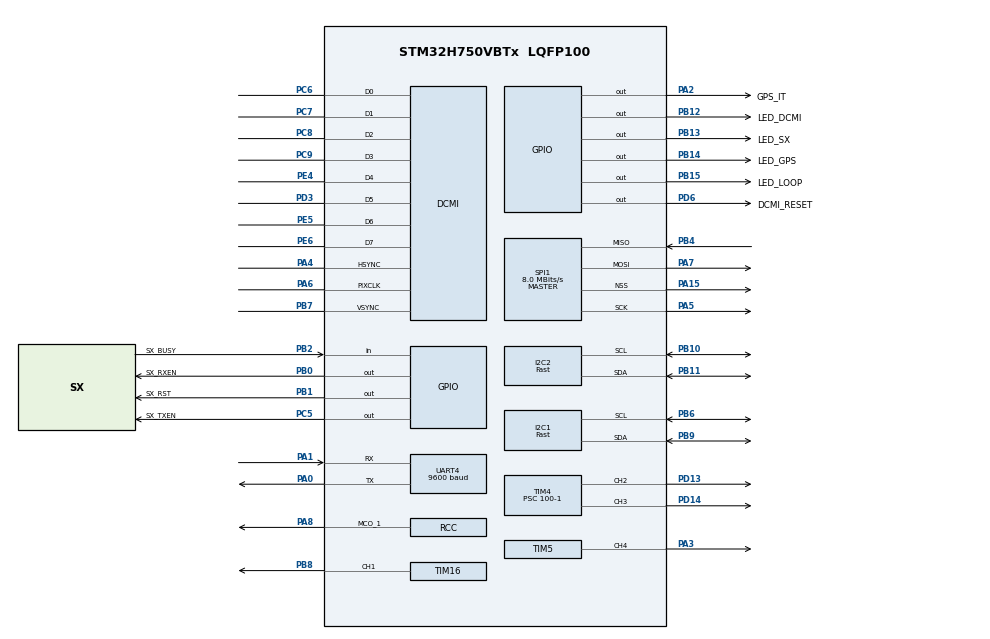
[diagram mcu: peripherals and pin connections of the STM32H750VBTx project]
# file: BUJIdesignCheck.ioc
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VP_TIM5_VS_ClockSourceINT.Mode=Internal
Dma.UART4_RX.1.Mode=DMA_CIRCULAR
Dma.UART4_RX.1.MemDataAlignment=DMA_MDATAALIGN_BYTE
I2C1.I2C_Speed_Mode=I2C_Fast
SPI1.VirtualType=VM_MASTER
PB10.Mode=I2C
RCC.PLL2_VCI_Range-AdvancedSettings=RCC_PLL2VCIRANGE_0
PB14.GPIO_Label=LED_GPS
Dma.DCMI.0.MemBurst=DMA_MBURST_SINGLE
PA15\ (JTDI).Signal=SPI1_NSS
PB13.Signal=GPIO_Output
PD6.GPIO_Label=DCMI_RESET
RCC.SYSCLKSource=RCC_SYSCLKSOURCE_PLLCLK
Dma.UART4_RX.1.SyncPolarity=HAL_DMAMUX_SYNC_NO_EVENT
Dma.DCMI.0.MemDataAlignment=DMA_MDATAALIGN_WORD
RCC.SPI123CLockSelection=RCC_SPI123CLKSOURCE_CLKP
PA15\ (JTDI).Mode=NSS_Signal_Hard_Output
PA14\ (JTCK/SWCLK).Signal=DEBUG_JTCK-SWCLK
PA4.Mode=Slave_8_bits_External_Synchro
Dma.DCMI.0.PeriphDataAlignment=DMA_PDATAALIGN_WORD
SPI1.Direction=SPI_DIRECTION_2LINES
I2C2.I2C_Speed_Mode=I2C_Fast
PB6.Signal=I2C1_SCL
PC7.Signal=DCMI_D1
PB12.PinState=GPIO_PIN_SET
PB6.Mode=I2C
SPI1.CalculateBaudRate=8.0 MBits/s
UART4.Parity=PARITY_NONE
PE5.Signal=DCMI_D6
Dma.UART4_RX.1.FIFOMode=DMA_FIFOMODE_DISABLE
TIM4.Channel-PWM\ Generation3\ CH3=TIM_CHANNEL_3
PB2.Signal=GPIO_Input
RCC.DIVM1=8
DCMI.PCKPolarity=DCMI_PCKPOLARITY_RISING
PB12.GPIO_Label=LED_DCMI
PB1.GPIO_Label=SX_RST
SPI1.DataSize=SPI_DATASIZE_8BIT
PA0.Mode=Asynchronous
PC9.Mode=Slave_8_bits_External_Synchro
SH.S_TIM4_CH2.0=TIM4_CH2,PWM Generation2 CH2
PA8.Signal=RCC_MCO_1
Dma.DCMI.0.Polarity=HAL_DMAMUX_REQ_GEN_RISING
PA14\ (JTCK/SWCLK).Mode=Serial_Wire
SPI1.VirtualNSS=VM_NSSHARD
RCC.PLL2_VCO_SEL-AdvancedSettings=RCC_PLL2VCOMEDIUM
TIM4.Period=5000-1
PD3.Mode=Slave_8_bits_External_Synchro
PA0.Signal=UART4_TX
Mcu.Package=LQFP100
PB9.Signal=I2C1_SDA
PB1.Signal=GPIO_Output
Dma.UART4_RX.1.PeriphDataAlignment=DMA_PDATAALIGN_BYTE
RCC.APB4Freq_Value=100000000
TIM16.Prescaler=100-1
I2C1.CustomTiming=Disabled
PH0-OSC_IN\ (PH0).Mode=HSE-External-Oscillator
NVIC.UART4_IRQn=true\:0\:0\:false\:false\:true\:true\:true
PA5.Mode=Full_Duplex_Master
TIM3.AutoReloadPreload=TIM_AUTORELOAD_PRELOAD_ENABLE
PD3.Signal=DCMI_D5
PC6.Signal=DCMI_D0
Dma.UART4_RX.1.SyncRequestNumber=1
SH.S_TIM16_CH1.0=TIM16_CH1,PWM Generation1 CH1
VP_TIM16_VS_ClockSourceINT.Mode=Enable_Timer
RCC.Tim2Mul=2
PB11.Mode=I2C
PC6.Mode=Slave_8_bits_External_Synchro
I2C1.Timing=0x009034B6
RCC.DIVN1=200
UART4.FIFOMode=FIFOMODE_DISABLE
PB10.Signal=I2C2_SCL
DCMI.JPEGMode=DCMI_JPEG_ENABLE
PB14.Signal=GPIO_Output
PA5.Signal=SPI1_SCK
Dma.DCMI.0.EventEnable=DISABLE
NVIC.TIM3_IRQn=true\:0\:0\:false\:false\:true\:true\:true
PA1.Mode=Asynchronous
PB13.PinState=GPIO_PIN_SET
PE6.Mode=Slave_8_bits_External_Synchro
PB15.GPIO_Label=LED_LOOP
SPI1.Mode=SPI_MODE_MASTER
PB4\ (NJTRST).Mode=Full_Duplex_Master
PC8.Mode=Slave_8_bits_External_Synchro
PA4.Signal=DCMI_HSYNC
ProjectManager.HeapSize=0x200
Dma.UART4_RX.1.PeriphInc=DMA_PINC_DISABLE
Dma.DCMI.0.SignalID=NONE
VP_TIM4_VS_ClockSourceINT.Mode=Internal
NVIC.PriorityGroup=NVIC_PRIORITYGROUP_4
Dma.UART4_RX.1.Priority=DMA_PRIORITY_LOW
PA8.Mode=Clock-out-1
Dma.DCMI.0.PeriphInc=DMA_PINC_DISABLE
Dma.UART4_RX.1.SignalID=NONE
PB0.Signal=GPIO_Output
PA13\ (JTMS/SWDIO).Signal=DEBUG_JTMS-SWDIO
Dma.DCMI.0.Priority=DMA_PRIORITY_VERY_HIGH
Mcu.Family=STM32H7
PA6.Mode=Slave_8_bits_External_Synchro
RCC.CortexFreq_Value=400000000
Dma.DCMI.0.SyncEnable=DISABLE
RCC.HPRE=RCC_HCLK_DIV2
PH0-OSC_IN\ (PH0).Signal=RCC_OSC_IN
I2C2.Timing=0x009034B6
TIM5.Pulse-PWM\ Generation4\ CH4=750
PB0.GPIO_Label=SX_RXEN
PB13.GPIO_Label=LED_SX
PB11.Signal=I2C2_SDA
PB15.Signal=GPIO_Output
PB15.PinState=GPIO_PIN_SET
ProjectManager.StackSize=0x400
Dma.DCMI.0.FIFOMode=DMA_FIFOMODE_ENABLE
Dma.UART4_RX.1.RequestNumber=1
PD13.Signal=S_TIM4_CH2
Dma.DCMI.0.FIFOThreshold=DMA_FIFO_THRESHOLD_FULL
Dma.UART4_RX.1.Polarity=HAL_DMAMUX_REQ_GEN_RISING
Dma.DCMI.0.MemInc=DMA_MINC_ENABLE
UART4.BaudRate=9600
RCC.HCLKFreq_Value=200000000
TIM3.Period=5000-1
RCC.HSE_VALUE=32000000
Dma.UART4_RX.1.EventEnable=DISABLE
PH1-OSC_OUT\ (PH1).Mode=HSE-External-Oscillator
Dma.UART4_RX.1.MemInc=DMA_MINC_DISABLE
RCC.PLL1_VCI_Range-AdvancedSettings=RCC_PLL1VCIRANGE_1
TIM5.Channel-PWM\ Generation4\ CH4=TIM_CHANNEL_4
TIM3.Prescaler=200-1
RCC.RCC_MCODiv1=RCC_MCODIV_2
PD6.PinState=GPIO_PIN_SET
PB7.Signal=DCMI_VSYNC
Dma.DCMI.0.PeriphBurst=DMA_PBURST_SINGLE
PE4.Mode=Slave_8_bits_External_Synchro
PE4.Signal=DCMI_D4
Dma.UART4_RX.1.SyncEnable=DISABLE
RCC.APB3Freq_Value=100000000
PA6.Signal=DCMI_PIXCLK
Dma.DCMI.0.Direction=DMA_PERIPH_TO_MEMORY
RCC.D1PPRE=RCC_APB3_DIV2
PA2.GPIO_Label=GPS_IT
Dma.Request1=UART4_RX
NVIC.DMA1_Stream0_IRQn=true\:0\:0\:false\:false\:true\:false\:true
PC5.Signal=GPIO_Output
PD6.Signal=GPIO_Output
Dma.Request0=DCMI
SPI1.BaudRatePrescaler=SPI_BAUDRATEPRESCALER_8
Dma.DCMI.0.SyncPolarity=HAL_DMAMUX_SYNC_NO_EVENT
VP_TIM3_VS_ClockSourceINT.Mode=Internal
Dma.UART4_RX.1.Direction=DMA_PERIPH_TO_MEMORY
Dma.UART4_RX.1.SyncSignalID=NONE
PA3.Signal=S_TIM5_CH4
RCC.PLLSourceVirtual=RCC_PLLSOURCE_HSE
PA7.Mode=Full_Duplex_Master
PA13\ (JTMS/SWDIO).Mode=Serial_Wire
PC8.Signal=DCMI_D2
RCC.D2PPRE2=RCC_APB2_DIV2
RCC.D2PPRE1=RCC_APB1_DIV2
NVIC.DMA1_Stream1_IRQn=true\:0\:0\:false\:false\:true\:false\:true
TIM16.Channel=TIM_CHANNEL_1
PH1-OSC_OUT\ (PH1).Signal=RCC_OSC_OUT
PB14.PinState=GPIO_PIN_SET
ProjectManager.TargetToolchain=STM32CubeIDE
SH.S_TIM4_CH3.0=TIM4_CH3,PWM Generation3 CH3
Dma.UART4_RX.1.Instance=DMA1_Stream1
PB9.Mode=I2C
Dma.DCMI.0.Instance=DMA1_Stream0
Dma.DCMI.0.Mode=DMA_CIRCULAR
RCC.USBFreq_Value=400000000
TIM4.Prescaler=100-1
PA1.Signal=UART4_RX
board=custom
Dma.DCMI.0.SyncSignalID=NONE
TIM4.Channel-PWM\ Generation2\ CH2=TIM_CHANNEL_2
TIM16.Period=5000-1
RCC.APB2Freq_Value=100000000
Dma.DCMI.0.RequestNumber=1
PB15.GPIO_Speed=GPIO_SPEED_FREQ_VERY_HIGH
PE5.Mode=Slave_8_bits_External_Synchro
RCC.ADCFreq_Value=64500000
SH.S_TIM5_CH4.0=TIM5_CH4,PWM Generation4 CH4
Dma.DCMI.0.SyncRequestNumber=1
PE6.Signal=DCMI_D7
Mcu.Name=STM32H750VBTx
PA2.Signal=GPIO_Output
PD14.Signal=S_TIM4_CH3
RCC.SYSCLKFreq_VALUE=400000000
TIM5.Prescaler=100-1
PC5.GPIO_Label=SX_TXEN
PB7.Mode=Slave_8_bits_External_Synchro
PB2.GPIO_Label=SX_BUSY
PB8.Signal=S_TIM16_CH1
RCC.D3PPRE=RCC_APB4_DIV2
TIM5.Period=5000-1
PC9.Signal=DCMI_D3
NVIC.DCMI_IRQn=true\:0\:0\:false\:false\:true\:true\:true
PC7.Mode=Slave_8_bits_External_Synchro
RCC.APB1Freq_Value=100000000
PB12.Signal=GPIO_Output
PA7.Signal=SPI1_MOSI
PB4\ (NJTRST).Signal=SPI1_MISO

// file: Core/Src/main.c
/* USER CODE BEGIN Header */
/**
  ******************************************************************************
  * @file           : main.c
  * @brief          : Main program body
  ******************************************************************************
  * @attention
  *
  * <h2><center>&copy; Copyright (c) 2020 STMicroelectronics.
  * All rights reserved.</center></h2>
  *
  * This software component is licensed by ST under BSD 3-Clause license,
  * the "License"; You may not use this file except in compliance with the
  * License. You may obtain a copy of the License at:
  *                        opensource.org/licenses/BSD-3-Clause
  *
  ******************************************************************************
  */
/* USER CODE END Header */
#include "main.h"
#include "dcmi.h"
#include "dma.h"
#include "i2c.h"
#include "spi.h"
#include "tim.h"
#include "usart.h"
#include "gpio.h"

/* USER CODE BEGIN Includes */
#include "CtrlCenter.h"
/* USER CODE END Includes */

/* USER CODE BEGIN PTD */
extern DCMI_HandleTypeDef hdcmi;
extern I2C_HandleTypeDef hi2c1;		//DCMI SCCB接口
extern I2C_HandleTypeDef hi2c2;		//JY61
extern UART_HandleTypeDef huart4;
/* USER CODE END PTD */

/* USER CODE BEGIN PM */
const GPS_INFO *testGPS;
Atti testAngle;
/* USER CODE END PM */

void SystemClock_Config(void);
void PeriphCommonClock_Config(void);

int main(void)
{

  /* MCU Configuration--------------------------------------------------------*/

  /* Reset of all peripherals, Initializes the Flash interface and the Systick. */
  HAL_Init();

  /* Configure the system clock */
  SystemClock_Config();

/* Configure the peripherals common clocks */
  PeriphCommonClock_Config();

  /* Initialize all configured peripherals */
  MX_GPIO_Init();
  MX_DMA_Init();
  MX_DCMI_Init();
  MX_I2C1_Init();
  MX_I2C2_Init();
  MX_SPI1_Init();
  MX_UART4_Init();
  MX_TIM4_Init();
  MX_TIM5_Init();
  MX_TIM16_Init();
  MX_TIM3_Init();
  /* USER CODE BEGIN 2 */
  ctrlCent.init();
  /* USER CODE END 2 */

  /* Infinite loop */
  while (1)
  {

  }
}

void SystemClock_Config(void)
{
  RCC_OscInitTypeDef RCC_OscInitStruct = {0};
  RCC_ClkInitTypeDef RCC_ClkInitStruct = {0};

  /** Supply configuration update enable
  */
  HAL_PWREx_ConfigSupply(PWR_LDO_SUPPLY);
  /** Configure the main internal regulator output voltage
  */
  __HAL_PWR_VOLTAGESCALING_CONFIG(PWR_REGULATOR_VOLTAGE_SCALE1);

  while(!__HAL_PWR_GET_FLAG(PWR_FLAG_VOSRDY)) {}
  /** Initializes the RCC Oscillators according to the specified parameters
  * in the RCC_OscInitTypeDef structure.
  */
  RCC_OscInitStruct.OscillatorType = RCC_OSCILLATORTYPE_HSI|RCC_OSCILLATORTYPE_HSE;
  RCC_OscInitStruct.HSEState = RCC_HSE_ON;
  RCC_OscInitStruct.HSIState = RCC_HSI_DIV1;
  RCC_OscInitStruct.HSICalibrationValue = RCC_HSICALIBRATION_DEFAULT;
  RCC_OscInitStruct.PLL.PLLState = RCC_PLL_ON;
  RCC_OscInitStruct.PLL.PLLSource = RCC_PLLSOURCE_HSE;
  RCC_OscInitStruct.PLL.PLLM = 8;
  RCC_OscInitStruct.PLL.PLLN = 200;
  RCC_OscInitStruct.PLL.PLLP = 2;
  RCC_OscInitStruct.PLL.PLLQ = 2;
  RCC_OscInitStruct.PLL.PLLR = 2;
  RCC_OscInitStruct.PLL.PLLRGE = RCC_PLL1VCIRANGE_2;
  RCC_OscInitStruct.PLL.PLLVCOSEL = RCC_PLL1VCOWIDE;
  RCC_OscInitStruct.PLL.PLLFRACN = 0;
  if (HAL_RCC_OscConfig(&RCC_OscInitStruct) != HAL_OK)
  {
    Error_Handler();
  }
  /** Initializes the CPU, AHB and APB buses clocks
  */
  RCC_ClkInitStruct.ClockType = RCC_CLOCKTYPE_HCLK|RCC_CLOCKTYPE_SYSCLK
                              |RCC_CLOCKTYPE_PCLK1|RCC_CLOCKTYPE_PCLK2
                              |RCC_CLOCKTYPE_D3PCLK1|RCC_CLOCKTYPE_D1PCLK1;
  RCC_ClkInitStruct.SYSCLKSource = RCC_SYSCLKSOURCE_PLLCLK;
  RCC_ClkInitStruct.SYSCLKDivider = RCC_SYSCLK_DIV1;
  RCC_ClkInitStruct.AHBCLKDivider = RCC_HCLK_DIV2;
  RCC_ClkInitStruct.APB3CLKDivider = RCC_APB3_DIV2;
  RCC_ClkInitStruct.APB1CLKDivider = RCC_APB1_DIV2;
  RCC_ClkInitStruct.APB2CLKDivider = RCC_APB2_DIV2;
  RCC_ClkInitStruct.APB4CLKDivider = RCC_APB4_DIV2;

  if (HAL_RCC_ClockConfig(&RCC_ClkInitStruct, FLASH_LATENCY_2) != HAL_OK)
  {
    Error_Handler();
  }
  HAL_RCC_MCOConfig(RCC_MCO1, RCC_MCO1SOURCE_HSI, RCC_MCODIV_2);
}

void PeriphCommonClock_Config(void)
{
  RCC_PeriphCLKInitTypeDef PeriphClkInitStruct = {0};

  /** Initializes the peripherals clock
  */
  PeriphClkInitStruct.PeriphClockSelection = RCC_PERIPHCLK_CKPER;
  PeriphClkInitStruct.CkperClockSelection = RCC_CLKPSOURCE_HSI;
  if (HAL_RCCEx_PeriphCLKConfig(&PeriphClkInitStruct) != HAL_OK)
  {
    Error_Handler();
  }
}

void Error_Handler(void)
{
}

/************************ (C) COPYRIGHT STMicroelectronics *****END OF FILE****/
